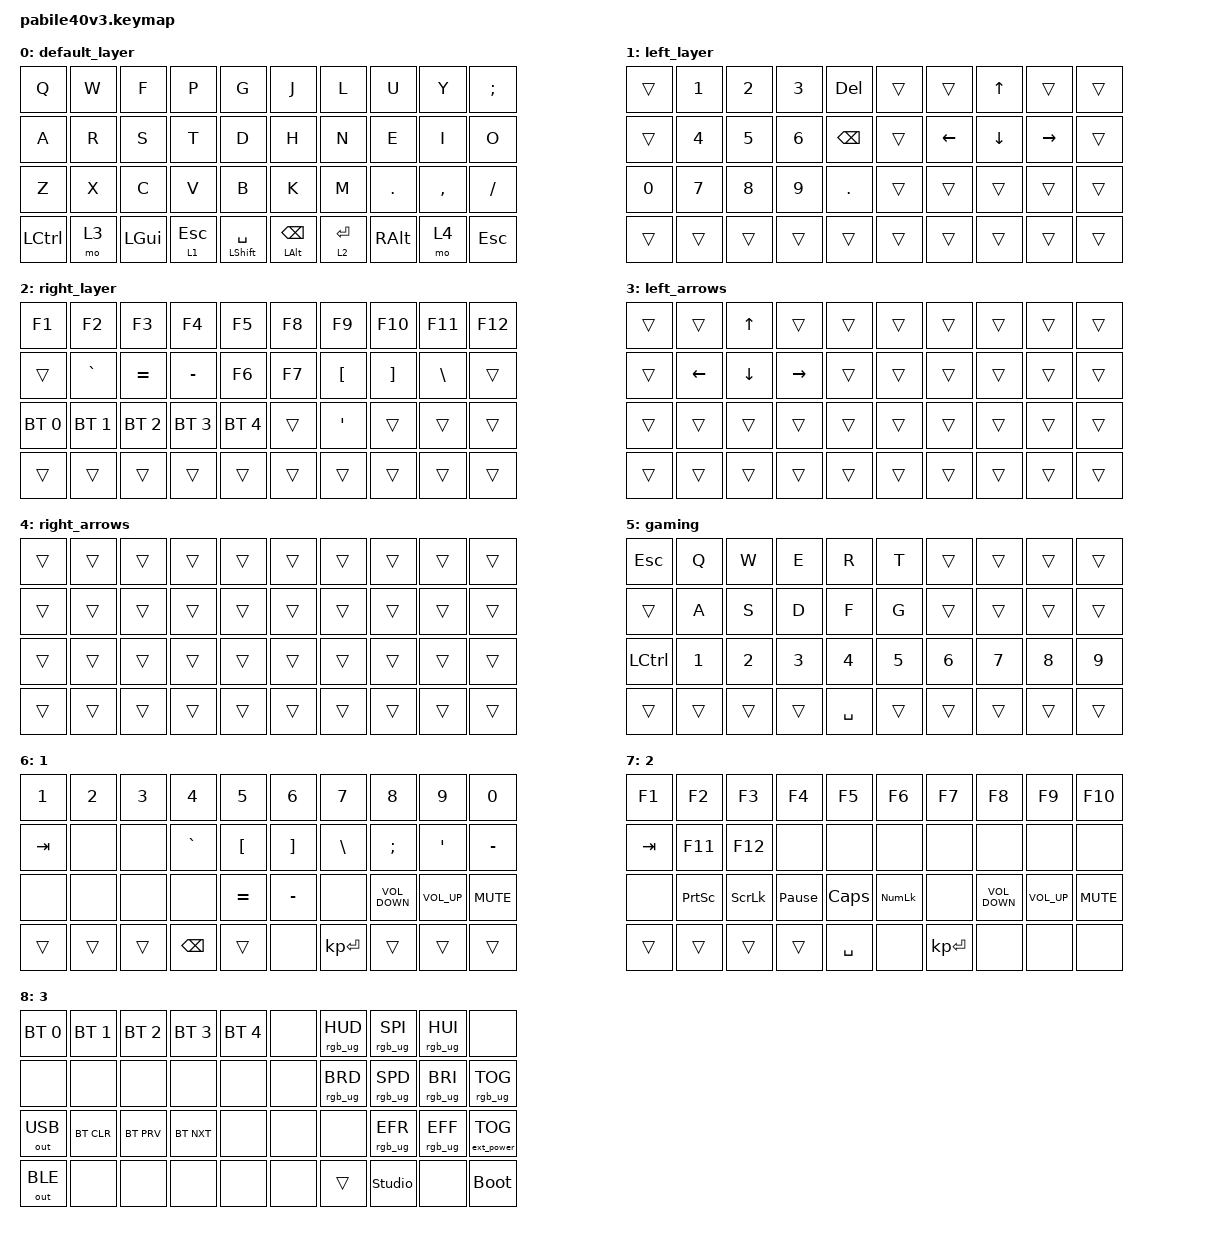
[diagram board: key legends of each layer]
/*
 * Copyright (c) 2023 The ZMK Contributors
 *
 * SPDX-License-Identifier: MIT
 */

#include <behaviors.dtsi>
#include <dt-bindings/zmk/keys.h>
#include <dt-bindings/zmk/bt.h>
#include <dt-bindings/zmk/outputs.h>
#include <dt-bindings/zmk/rgb.h>
#include <dt-bindings/zmk/ext_power.h>
#include <dt-bindings/zmk/pointing.h>

#include <behaviors.dtsi>
#include <dt-bindings/zmk/bt.h>
#include <dt-bindings/zmk/keys.h>

#include <behaviors.dtsi>
#include <dt-bindings/zmk/bt.h>
#include <dt-bindings/zmk/keys.h>

#include <behaviors.dtsi>
#include <dt-bindings/zmk/bt.h>
#include <dt-bindings/zmk/keys.h>

/ {
    combos {
        compatible = "zmk,combos";

        copy_combo {
            bindings = <&copy_macro>;
            key-positions = <13 12>;
            timeout-ms = <30>;
            require-prior-idle-ms = <30>;
            layers = <0>;
        };

        cut_combo {
            bindings = <&cut_macro>;
            key-positions = <13 2>;
            timeout-ms = <30>;
            require-prior-idle-ms = <30>;
            layers = <0>;
        };

        paste_combo {
            bindings = <&paste_macro>;
            key-positions = <13 22>;
            timeout-ms = <30>;
            require-prior-idle-ms = <30>;
            layers = <0>;
        };

        save_combo {
            bindings = <&save_macro>;
            key-positions = <12 11>;
            timeout-ms = <30>;
            require-prior-idle-ms = <30>;
            layers = <0>;
        };

        undo_combo {
            bindings = <&undo_macro>;
            key-positions = <21 22>;
            timeout-ms = <30>;
            require-prior-idle-ms = <30>;
            layers = <0>;
        };

        redo_combo {
            bindings = <&redo_macro>;
            key-positions = <21 23>;
            timeout-ms = <30>;
            require-prior-idle-ms = <30>;
            layers = <0>;
        };

        enter_combo {
            bindings = <&kp ENTER>;
            key-positions = <23 22>;
            timeout-ms = <30>;
            require-prior-idle-ms = <30>;
            layers = <0>;
        };

        tab_combo {
            bindings = <&kp TAB>;
            key-positions = <13 10>;
            timeout-ms = <30>;
            require-prior-idle-ms = <30>;
            layers = <0>;
        };

        select_all_combo {
            bindings = <&select_all_macro>;
            key-positions = <13 11>;
            timeout-ms = <30>;
            require-prior-idle-ms = <30>;
            layers = <0>;
        };
    };

    macros {
        copy_macro: copy_macro {
            compatible = "zmk,behavior-macro";
            #binding-cells = <0>;
            bindings =
                <&macro_press>,
                <&kp LCTRL>,
                <&macro_tap>,
                <&kp C>,
                <&macro_release>,
                <&kp LCTRL>;

            label = "COPY_MACRO";
        };

        cut_macro: cut_macro {
            compatible = "zmk,behavior-macro";
            #binding-cells = <0>;
            bindings =
                <&macro_press>,
                <&kp LCTRL>,
                <&macro_tap>,
                <&kp X>,
                <&macro_release>,
                <&kp LCTRL>;

            label = "CUT_MACRO";
        };

        paste_macro: paste_macro {
            compatible = "zmk,behavior-macro";
            #binding-cells = <0>;
            bindings =
                <&macro_press>,
                <&kp LCTRL>,
                <&macro_tap>,
                <&kp V>,
                <&macro_release>,
                <&kp LCTRL>;

            label = "PASTE_MACRO";
        };

        select_all_macro: select_all_macro {
            compatible = "zmk,behavior-macro";
            #binding-cells = <0>;
            bindings =
                <&macro_press>,
                <&kp LCTRL>,
                <&macro_tap>,
                <&kp A>,
                <&macro_release>,
                <&kp LCTRL>;

            label = "SELECT_ALL_MACRO";
        };

        undo_macro: undo_macro {
            compatible = "zmk,behavior-macro";
            #binding-cells = <0>;
            bindings =
                <&macro_press>,
                <&kp LCTRL>,
                <&macro_tap>,
                <&kp Z>,
                <&macro_release>,
                <&kp LCTRL>;

            label = "UNDO_MACRO";
        };

        redo_macro: redo_macro {
            compatible = "zmk,behavior-macro";
            #binding-cells = <0>;
            bindings =
                <&macro_press>,
                <&kp LCTRL &kp LEFT_SHIFT>,
                <&macro_tap>,
                <&kp Z>,
                <&macro_release>,
                <&kp LCTRL &kp LEFT_SHIFT>;

            label = "REDO_MACRO";
        };

        save_macro: save_macro {
            compatible = "zmk,behavior-macro";
            #binding-cells = <0>;
            bindings =
                <&macro_press>,
                <&kp LCTRL>,
                <&macro_tap>,
                <&kp S>,
                <&macro_release>,
                <&kp LCTRL>;

            label = "SAVE_MACRO";
        };
    };

    keymap {
        compatible = "zmk,keymap";

        default_layer {
            // --------------------------------------------------------------------------
            // |  Q   |  W   |  E   |  R   |  T   |   Y   |  U    |  I   |  O   |   P   | 
            // |  A   |  S   |  D   |  F   |  G   |   H   |  J    |  K   |  L   |   -   | 
            // |  Z   |  X   |  C   |  V   |  B   |   N   |  M    |  ,   |  .   |   /   |
            // | LCTL | LALT | LSHFT| BSPC | SPACE        |  ENT  | DEL  | RGUI | ESC   |

            bindings = <
&kp Q  &kp W  &kp F  &kp P  &kp G  &kp J  &kp L  &kp U  &kp Y  &kp SEMI  &kp A  &kp R  &kp S  &kp T  &kp D  &kp H  &kp N  &kp E  &kp I  &kp O  &kp Z  &kp X  &kp C  &kp V  &kp B  &kp K  &kp M  &kp DOT  &kp COMMA  &kp FSLH  &kp LCTRL  &mo 3  &kp LGUI  &lt 1 ESCAPE  &mt LEFT_SHIFT SPACE  &mt LEFT_ALT BACKSPACE  &lt 2 ENTER  &kp RIGHT_ALT  &mo 4  &kp ESC
            >;
        };

        left_layer {
            bindings = <
&trans  &kp N1  &kp N2  &kp N3  &kp DELETE  &trans  &trans  &kp UP  &trans  &trans  &trans  &kp N4  &kp N5  &kp N6  &kp BSPC  &trans  &kp LEFT  &kp DOWN  &kp RIGHT  &trans  &kp N0  &kp N7  &kp N8  &kp N9  &kp DOT  &trans  &trans  &trans  &trans  &trans  &trans  &trans  &trans  &trans  &trans  &trans  &trans  &trans  &trans  &trans
            >;
        };

        right_layer {
            bindings = <
&kp F1  &kp F2  &kp F3  &kp F4  &kp F5  &kp F8  &kp F9  &kp F10  &kp F11  &kp F12  &trans  &kp GRAVE  &kp EQUAL  &kp MINUS  &kp F6  &kp F7  &kp LBKT  &kp RBKT  &kp BSLH  &trans  &bt BT_SEL 0  &bt BT_SEL 1  &bt BT_SEL 2  &bt BT_SEL 3  &bt BT_SEL 4  &trans  &kp APOS  &trans  &trans  &trans  &trans  &trans  &trans  &trans  &trans  &trans  &trans  &trans  &trans  &trans
            >;
        };

        left_arrows {
            bindings = <
&trans  &trans  &kp UP  &trans  &trans  &trans  &trans  &trans  &trans  &trans  &trans  &kp LEFT  &kp DOWN  &kp RIGHT  &trans  &trans  &trans  &trans  &trans  &trans  &trans  &trans  &trans  &trans  &trans  &trans  &trans  &trans  &trans  &trans  &trans  &trans  &trans  &trans  &trans  &trans  &trans  &trans  &trans  &trans
            >;
        };

        right_arrows {
            bindings = <
&trans  &trans  &trans  &trans  &trans  &trans  &trans  &trans  &trans  &trans  &trans  &trans  &trans  &trans  &trans  &trans  &trans  &trans  &trans  &trans  &trans  &trans  &trans  &trans  &trans  &trans  &trans  &trans  &trans  &trans  &trans  &trans  &trans  &trans  &trans  &trans  &trans  &trans  &trans  &trans
            >;
        };

        gaming {
            bindings = <
&kp ESC  &kp Q  &kp W  &kp E  &kp R  &kp T  &trans  &trans  &trans  &trans  &trans  &kp A  &kp S  &kp D  &kp F  &kp G  &trans  &trans  &trans  &trans  &kp LCTRL  &kp N1  &kp N2  &kp N3  &kp N4  &kp N5  &kp N6  &kp N7  &kp N8  &kp N9  &trans  &trans  &trans  &trans  &kp SPACE  &trans  &trans  &trans  &trans  &trans
            >;
        };

        1 {

        bindings = <
				&kp N1   &kp N2    &kp N3   &kp N4     &kp N5     &kp N6     &kp N7       &kp N8    &kp N9   &kp N0
				&kp TAB  &none     &none    &kp GRAVE  &kp LBKT   &kp RBKT   &kp BSLH     &kp SEMI  &kp SQT  &kp MINUS
				&none    &none     &none    &none      &kp EQUAL  &kp MINUS  &none        &kp C_VOLUME_DOWN &kp C_VOLUME_UP &kp C_MUTE
				&trans   &trans   &trans    &kp BSPC   &trans     &none      &kp KP_ENTER &trans    &trans   &trans
        >;
    };

    2 {

    bindings = <
				&kp F1   &kp F2    &kp F3   &kp F4     &kp F5     &kp F6          &kp F7       &kp F8            &kp F9          &kp F10
				&kp TAB  &kp F11   &kp F12  &none      &none      &none           &none        &none             &none           &none
				&none    &kp PSCRN &kp SLCK &kp PAUSE_BREAK  &kp CAPS  &kp KP_NUMLOCK  &none   &kp C_VOLUME_DOWN &kp C_VOLUME_UP &kp C_MUTE
				&trans   &trans    &trans   &trans     &kp SPACE  &none           &kp KP_ENTER &none             &none           &none
    >;
};

3 {
			bindings = <
				&trans        &mkp LCLK      &mmv MOVE_UP   &mkp RCLK       &msc SCRL_UP     &kp INS      &kp PAGE_UP  &kp UP     &kp PAGE_DOWN      &kp DEL
				&trans        &mmv MOVE_LEFT &mmv MOVE_DOWN &mmv MOVE_RIGHT &msc SCRL_DOWN   &kp HOME     &kp LEFT     &kp DOWN   &kp RIGHT          &none
				&none         &none          &none          &none           &none     &kp END      &none        &none      &none              &none
				&trans        &trans         &kp BSPC       &kp SPACE       &none     &trans       &trans       &trans     &trans

&trans {
    >;
};

4

    bindings = <
				&bt BT_SEL 0  &bt BT_SEL 1 &bt BT_SEL 2 &bt BT_SEL 3 &bt BT_SEL 4 &none    &rgb_ug RGB_HUD  &rgb_ug RGB_SPI  &rgb_ug RGB_HUI  &none
				&none         &none        &none        &none        &none        &none    &rgb_ug RGB_BRD  &rgb_ug RGB_SPD  &rgb_ug RGB_BRI  &rgb_ug RGB_TOG
				&out OUT_USB  &bt BT_CLR   &bt BT_PRV   &bt BT_NXT   &none        &none    &none            &rgb_ug RGB_EFR  &rgb_ug RGB_EFF  &ext_power EP_TOG
				&out OUT_BLE  &none        &none        &none        &none        &none    &trans           &studio_unlock   &none            &bootloader
    >;
};

&lt {
    tapping-term-ms = <100>;
    flavor = "tap-unless-interrupted";
};

&mt { flavor = "tap-unless-interrupted"; };

};
};
